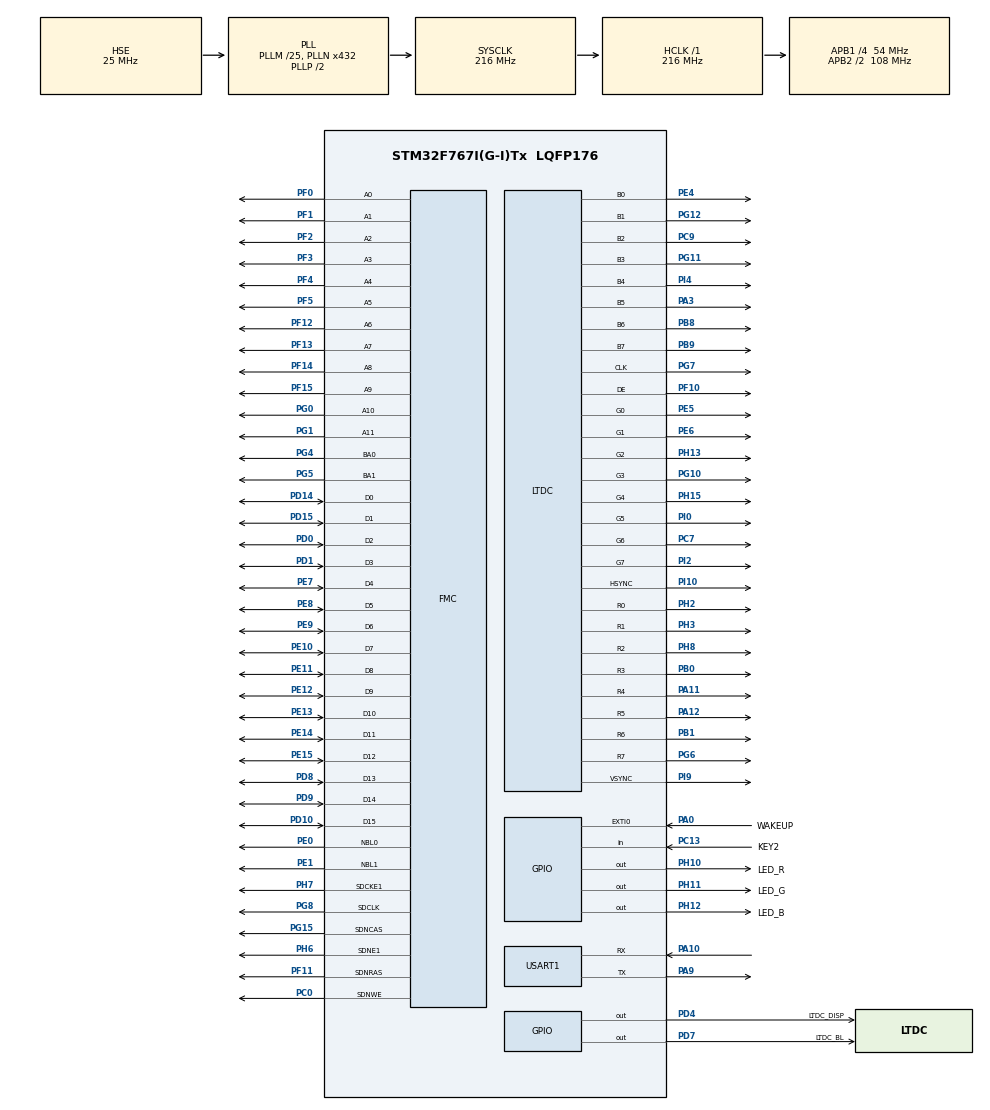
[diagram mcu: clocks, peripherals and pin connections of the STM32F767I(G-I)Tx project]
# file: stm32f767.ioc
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CORTEX_M7.CPU_DCache=Enabled
CORTEX_M7.CPU_ICache=Enabled
DMA2D.ColorMode=DMA2D_OUTPUT_ARGB8888
DMA2D.Mode=DMA2D_R2M
Dma.Request0=USART1_RX
Dma.Request1=USART1_TX
Dma.USART1_RX.0.Direction=DMA_PERIPH_TO_MEMORY
Dma.USART1_RX.0.FIFOMode=DMA_FIFOMODE_DISABLE
Dma.USART1_RX.0.Instance=DMA2_Stream2
Dma.USART1_RX.0.MemDataAlignment=DMA_MDATAALIGN_BYTE
Dma.USART1_RX.0.MemInc=DMA_MINC_ENABLE
Dma.USART1_RX.0.Mode=DMA_NORMAL
Dma.USART1_RX.0.PeriphDataAlignment=DMA_PDATAALIGN_BYTE
Dma.USART1_RX.0.PeriphInc=DMA_PINC_DISABLE
Dma.USART1_RX.0.Priority=DMA_PRIORITY_LOW
Dma.USART1_TX.1.Direction=DMA_MEMORY_TO_PERIPH
Dma.USART1_TX.1.FIFOMode=DMA_FIFOMODE_DISABLE
Dma.USART1_TX.1.Instance=DMA2_Stream7
Dma.USART1_TX.1.MemDataAlignment=DMA_MDATAALIGN_BYTE
Dma.USART1_TX.1.MemInc=DMA_MINC_ENABLE
Dma.USART1_TX.1.Mode=DMA_NORMAL
Dma.USART1_TX.1.PeriphDataAlignment=DMA_PDATAALIGN_BYTE
Dma.USART1_TX.1.PeriphInc=DMA_PINC_DISABLE
Dma.USART1_TX.1.Priority=DMA_PRIORITY_LOW
FMC.CASLatency1=FMC_SDRAM_CAS_LATENCY_3
FMC.ExitSelfRefreshDelay1=7
FMC.LoadToActiveDelay1=2
FMC.RCDDelay1=2
FMC.RPDelay1=2
FMC.RPDelay2=2
FMC.ReadBurst1=FMC_SDRAM_RBURST_ENABLE
FMC.ReadBurst2=FMC_SDRAM_RBURST_ENABLE
FMC.ReadPipeDelay1=FMC_SDRAM_RPIPE_DELAY_1
FMC.ReadPipeDelay2=FMC_SDRAM_RPIPE_DELAY_1
FMC.RowCycleDelay1=6
FMC.RowCycleDelay2=6
FMC.SDClockPeriod1=FMC_SDRAM_CLOCK_PERIOD_2
FMC.SDClockPeriod2=FMC_SDRAM_CLOCK_PERIOD_2
FMC.SelfRefreshTime1=4
FMC.WriteRecoveryTime1=2
LTDC.ActiveW=800
LTDC.Alpha_L0=255
LTDC.Alpha_L1=0
LTDC.BlendingFactor1_L0=LTDC_BLENDING_FACTOR1_PAxCA
LTDC.BlendingFactor1_L1=LTDC_BLENDING_FACTOR1_PAxCA
LTDC.BlendingFactor2_L0=LTDC_BLENDING_FACTOR2_PAxCA
LTDC.BlendingFactor2_L1=LTDC_BLENDING_FACTOR2_PAxCA
LTDC.FBStartAdress_L0=0xD0000000
LTDC.FBStartAdress_L1=0xD0200000
LTDC.HBP=46
LTDC.HFP=10
LTDC.HSync=1
LTDC.ImageHeight_L0=480
LTDC.ImageHeight_L1=480
LTDC.ImageWidth_L0=800
LTDC.ImageWidth_L1=800
LTDC.Layers=1
LTDC.PixelFormat_L0=LTDC_PIXEL_FORMAT_ARGB8888
LTDC.PixelFormat_L1=LTDC_PIXEL_FORMAT_ARGB8888
LTDC.VBP=23
LTDC.VFP=22
LTDC.WindowX1_L0=800
LTDC.WindowX1_L1=800
LTDC.WindowY1_L0=480
LTDC.WindowY1_L1=480
Mcu.Family=STM32F7
Mcu.Name=STM32F767I(G-I)Tx
Mcu.Package=LQFP176
NVIC.DMA2D_IRQn=true\:0\:0\:false\:false\:true\:true
NVIC.DMA2_Stream2_IRQn=true\:0\:0\:false\:false\:true\:false
NVIC.DMA2_Stream7_IRQn=true\:0\:0\:false\:false\:true\:false
NVIC.EXTI0_IRQn=true\:0\:0\:false\:false\:true\:true
NVIC.LTDC_IRQn=true\:0\:0\:false\:false\:true\:true
NVIC.PriorityGroup=NVIC_PRIORITYGROUP_4
PA0/WKUP.GPIO_Label=WAKEUP
PA0/WKUP.Signal=GPXTI0
PA10.Mode=Asynchronous
PA10.Signal=USART1_RX
PA11.GPIO_Speed=GPIO_SPEED_FREQ_VERY_HIGH
PA11.Mode=RGB888
PA11.Signal=LTDC_R4
PA12.GPIO_Speed=GPIO_SPEED_FREQ_VERY_HIGH
PA12.Mode=RGB888
PA12.Signal=LTDC_R5
PA3.GPIO_Speed=GPIO_SPEED_FREQ_VERY_HIGH
PA3.Mode=RGB888
PA3.Signal=LTDC_B5
PA9.Mode=Asynchronous
PA9.Signal=USART1_TX
PB0.GPIO_Speed=GPIO_SPEED_FREQ_VERY_HIGH
PB0.Mode=RGB888
PB0.Signal=LTDC_R3
PB1.GPIO_Speed=GPIO_SPEED_FREQ_VERY_HIGH
PB1.Mode=RGB888
PB1.Signal=LTDC_R6
PB8.GPIO_Speed=GPIO_SPEED_FREQ_VERY_HIGH
PB8.Mode=RGB888
PB8.Signal=LTDC_B6
PB9.GPIO_Speed=GPIO_SPEED_FREQ_VERY_HIGH
PB9.Mode=RGB888
PB9.Signal=LTDC_B7
PC0.Signal=FMC_SDNWE
PC13.GPIO_Label=KEY2
PC13.Signal=GPIO_Input
PC7.GPIO_Speed=GPIO_SPEED_FREQ_VERY_HIGH
PC7.Mode=RGB888
PC7.Signal=LTDC_G6
PC9.Mode=RGB888
PC9.Signal=LTDC_B2
PD0.Signal=FMC_D2_DA2
PD1.Signal=FMC_D3_DA3
PD10.Signal=FMC_D15_DA15
PD14.Signal=FMC_D0_DA0
PD15.Signal=FMC_D1_DA1
PD4.GPIO_Label=LTDC_DISP
PD4.GPIO_PuPd=GPIO_PULLUP
PD4.GPIO_Speed=GPIO_SPEED_FREQ_HIGH
PD4.Signal=GPIO_Output
PD7.GPIO_Label=LTDC_BL
PD7.GPIO_PuPd=GPIO_PULLUP
PD7.GPIO_Speed=GPIO_SPEED_FREQ_HIGH
PD7.Signal=GPIO_Output
PD8.Signal=FMC_D13_DA13
PD9.Signal=FMC_D14_DA14
PE0.Signal=FMC_NBL0
PE1.Signal=FMC_NBL1
PE10.Signal=FMC_D7_DA7
PE11.Signal=FMC_D8_DA8
PE12.Signal=FMC_D9_DA9
PE13.Signal=FMC_D10_DA10
PE14.Signal=FMC_D11_DA11
PE15.Signal=FMC_D12_DA12
PE4.Mode=RGB888
PE4.Signal=LTDC_B0
PE5.Mode=RGB888
PE5.Signal=LTDC_G0
PE6.Mode=RGB888
PE6.Signal=LTDC_G1
PE7.Signal=FMC_D4_DA4
PE8.Signal=FMC_D5_DA5
PE9.Signal=FMC_D6_DA6
PF0.Signal=FMC_A0
PF1.Signal=FMC_A1
PF10.GPIO_Speed=GPIO_SPEED_FREQ_VERY_HIGH
PF10.Mode=RGB888
PF10.Signal=LTDC_DE
PF11.Signal=FMC_SDNRAS
PF12.Signal=FMC_A6
PF13.Signal=FMC_A7
PF14.Signal=FMC_A8
PF15.Signal=FMC_A9
PF2.Signal=FMC_A2
PF3.Signal=FMC_A3
PF4.Signal=FMC_A4
PF5.Signal=FMC_A5
PG0.Signal=FMC_A10
PG1.Signal=FMC_A11
PG10.GPIO_Speed=GPIO_SPEED_FREQ_VERY_HIGH
PG10.Mode=RGB888
PG10.Signal=LTDC_G3
PG11.GPIO_Speed=GPIO_SPEED_FREQ_VERY_HIGH
PG11.Mode=RGB888
PG11.Signal=LTDC_B3
PG12.Mode=RGB888
PG12.Signal=LTDC_B1
PG15.Signal=FMC_SDNCAS
PG4.Signal=FMC_A14_BA0
PG5.Signal=FMC_A15_BA1
PG6.GPIO_Speed=GPIO_SPEED_FREQ_VERY_HIGH
PG6.Mode=RGB888
PG6.Signal=LTDC_R7
PG7.GPIO_Speed=GPIO_SPEED_FREQ_VERY_HIGH
PG7.Mode=RGB888
PG7.Signal=LTDC_CLK
PG8.Signal=FMC_SDCLK
PH0/OSC_IN.Mode=HSE-External-Oscillator
PH0/OSC_IN.Signal=RCC_OSC_IN
PH1/OSC_OUT.Mode=HSE-External-Oscillator
PH1/OSC_OUT.Signal=RCC_OSC_OUT
PH10.GPIO_Label=LED_R
PH10.GPIO_PuPd=GPIO_PULLUP
PH10.Signal=GPIO_Output
PH11.GPIO_Label=LED_G
PH11.GPIO_PuPd=GPIO_PULLUP
PH11.Signal=GPIO_Output
PH12.GPIO_Label=LED_B
PH12.GPIO_PuPd=GPIO_PULLUP
PH12.Signal=GPIO_Output
PH13.GPIO_Speed=GPIO_SPEED_FREQ_VERY_HIGH
PH13.Mode=RGB888
PH13.Signal=LTDC_G2
PH15.GPIO_Speed=GPIO_SPEED_FREQ_VERY_HIGH
PH15.Mode=RGB888
PH15.Signal=LTDC_G4
PH2.Mode=RGB888
PH2.Signal=LTDC_R0
PH3.GPIO_Speed=GPIO_SPEED_FREQ_VERY_HIGH
PH3.Mode=RGB888
PH3.Signal=LTDC_R1
PH6.Mode=SdramChipSelect2_1
PH6.Signal=FMC_SDNE1
PH7.Mode=SdramChipSelect2_1
PH7.Signal=FMC_SDCKE1
PH8.GPIO_Speed=GPIO_SPEED_FREQ_VERY_HIGH
PH8.Mode=RGB888
PH8.Signal=LTDC_R2
PI0.GPIO_Speed=GPIO_SPEED_FREQ_VERY_HIGH
PI0.Mode=RGB888
PI0.Signal=LTDC_G5
PI10.Mode=RGB888
PI10.Signal=LTDC_HSYNC
PI2.GPIO_Speed=GPIO_SPEED_FREQ_VERY_HIGH
PI2.Mode=RGB888
PI2.Signal=LTDC_G7
PI4.GPIO_Speed=GPIO_SPEED_FREQ_VERY_HIGH
PI4.Mode=RGB888
PI4.Signal=LTDC_B4
PI9.GPIO_Speed=GPIO_SPEED_FREQ_VERY_HIGH
PI9.Mode=RGB888
PI9.Signal=LTDC_VSYNC
ProjectManager.HeapSize=0x200
ProjectManager.StackSize=0x1000
ProjectManager.TargetToolchain=MDK-ARM V5
RCC.AHBFreq_Value=216000000
RCC.APB1CLKDivider=RCC_HCLK_DIV4
RCC.APB1Freq_Value=54000000
RCC.APB1TimFreq_Value=108000000
RCC.APB2CLKDivider=RCC_HCLK_DIV2
RCC.APB2Freq_Value=108000000
RCC.APB2TimFreq_Value=216000000
RCC.CortexFreq_Value=216000000
RCC.HCLKFreq_Value=216000000
RCC.HSE_VALUE=25000000
RCC.HSI_VALUE=16000000
RCC.LSE_VALUE=32768
RCC.PLLM=25
RCC.PLLN=432
RCC.PLLQ=9
RCC.PLLSAIR=5
RCC.PLLSAIRDiv=RCC_PLLSAIDIVR_4
RCC.PLLSourceVirtual=RCC_PLLSOURCE_HSE
RCC.SYSCLKFreq_VALUE=216000000
RCC.SYSCLKSource=RCC_SYSCLKSOURCE_PLLCLK
RCC.USBFreq_Value=48000000
RCC.VCOOutputFreq_Value=432000000
SH.FMC_A0.0=FMC_A0,12b-sda1
SH.FMC_A1.0=FMC_A1,12b-sda1
SH.FMC_A10.0=FMC_A10,12b-sda1
SH.FMC_A11.0=FMC_A11,12b-sda1
SH.FMC_A14_BA0.0=FMC_BA0,FourSdramBanks1
SH.FMC_A15_BA1.0=FMC_BA1,FourSdramBanks1
SH.FMC_A2.0=FMC_A2,12b-sda1
SH.FMC_A3.0=FMC_A3,12b-sda1
SH.FMC_A4.0=FMC_A4,12b-sda1
SH.FMC_A5.0=FMC_A5,12b-sda1
SH.FMC_A6.0=FMC_A6,12b-sda1
SH.FMC_A7.0=FMC_A7,12b-sda1
SH.FMC_A8.0=FMC_A8,12b-sda1
SH.FMC_A9.0=FMC_A9,12b-sda1
SH.FMC_D0_DA0.0=FMC_D0,sd-16b-d1
SH.FMC_D10_DA10.0=FMC_D10,sd-16b-d1
SH.FMC_D11_DA11.0=FMC_D11,sd-16b-d1
SH.FMC_D12_DA12.0=FMC_D12,sd-16b-d1
SH.FMC_D13_DA13.0=FMC_D13,sd-16b-d1
SH.FMC_D14_DA14.0=FMC_D14,sd-16b-d1
SH.FMC_D15_DA15.0=FMC_D15,sd-16b-d1
SH.FMC_D1_DA1.0=FMC_D1,sd-16b-d1
SH.FMC_D2_DA2.0=FMC_D2,sd-16b-d1
SH.FMC_D3_DA3.0=FMC_D3,sd-16b-d1
SH.FMC_D4_DA4.0=FMC_D4,sd-16b-d1
SH.FMC_D5_DA5.0=FMC_D5,sd-16b-d1
SH.FMC_D6_DA6.0=FMC_D6,sd-16b-d1
SH.FMC_D7_DA7.0=FMC_D7,sd-16b-d1
SH.FMC_D8_DA8.0=FMC_D8,sd-16b-d1
SH.FMC_D9_DA9.0=FMC_D9,sd-16b-d1
SH.FMC_NBL0.0=FMC_NBL0,Sd2ByteEnable1
SH.FMC_NBL1.0=FMC_NBL1,Sd2ByteEnable1
SH.FMC_SDCLK.0=FMC_SDCLK,12b-sda1
SH.FMC_SDNCAS.0=FMC_SDNCAS,12b-sda1
SH.FMC_SDNRAS.0=FMC_SDNRAS,12b-sda1
SH.FMC_SDNWE.0=FMC_SDNWE,12b-sda1
USART1.VirtualMode-Asynchronous=VM_ASYNC
VP_DMA2D_VS_DMA2D.Mode=DMA2D_Activate
board=custom

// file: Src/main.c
/**
  ******************************************************************************
  * @file           : main.c
  * @brief          : Main program body
  ******************************************************************************
  ** This notice applies to any and all portions of this file
  * that are not between comment pairs USER CODE BEGIN and
  * USER CODE END. Other portions of this file, whether
  * inserted by the user or by software development tools
  * are owned by their respective copyright owners.
  *
  * COPYRIGHT(c) 2018 STMicroelectronics
  *
  * Redistribution and use in source and binary forms, with or without modification,
  * are permitted provided that the following conditions are met:
  *   1. Redistributions of source code must retain the above copyright notice,
  *      this list of conditions and the following disclaimer.
  *   2. Redistributions in binary form must reproduce the above copyright notice,
  *      this list of conditions and the following disclaimer in the documentation
  *      and/or other materials provided with the distribution.
  *   3. Neither the name of STMicroelectronics nor the names of its contributors
  *      may be used to endorse or promote products derived from this software
  *      without specific prior written permission.
  *
  * THIS SOFTWARE IS PROVIDED BY THE COPYRIGHT HOLDERS AND CONTRIBUTORS "AS IS"
  * AND ANY EXPRESS OR IMPLIED WARRANTIES, INCLUDING, BUT NOT LIMITED TO, THE
  * IMPLIED WARRANTIES OF MERCHANTABILITY AND FITNESS FOR A PARTICULAR PURPOSE ARE
  * DISCLAIMED. IN NO EVENT SHALL THE COPYRIGHT HOLDER OR CONTRIBUTORS BE LIABLE
  * FOR ANY DIRECT, INDIRECT, INCIDENTAL, SPECIAL, EXEMPLARY, OR CONSEQUENTIAL
  * DAMAGES (INCLUDING, BUT NOT LIMITED TO, PROCUREMENT OF SUBSTITUTE GOODS OR
  * SERVICES; LOSS OF USE, DATA, OR PROFITS; OR BUSINESS INTERRUPTION) HOWEVER
  * CAUSED AND ON ANY THEORY OF LIABILITY, WHETHER IN CONTRACT, STRICT LIABILITY,
  * OR TORT (INCLUDING NEGLIGENCE OR OTHERWISE) ARISING IN ANY WAY OUT OF THE USE
  * OF THIS SOFTWARE, EVEN IF ADVISED OF THE POSSIBILITY OF SUCH DAMAGE.
  *
  ******************************************************************************
  */
#include "main.h"
#include "stm32f7xx_hal.h"
#include "dma.h"
#include "dma2d.h"
#include "ltdc.h"
#include "usart.h"
#include "gpio.h"
#include "fmc.h"

/* USER CODE BEGIN Includes */
#include "stdio.h"
#include <string.h>
#include "../Drivers/BSP/Components/std800480/std800480.h"
//#include "image1.h"

/* USER CODE END Includes */

/* USER CODE BEGIN PV */
/* Private variables ---------------------------------------------------------*/
uint32_t read_buffer[200];

/* USER CODE END PV */

void SystemClock_Config(void);

/* USER CODE BEGIN PFP */
/* Private function prototypes -----------------------------------------------*/
void lcd_init(void);
void sdram_init(void);
/* USER CODE END PFP */

int main(void)
{

  /* Enable I-Cache-------------------------------------------------------------*/
  SCB_EnableICache();

  /* Enable D-Cache-------------------------------------------------------------*/
  SCB_EnableDCache();

  /* MCU Configuration----------------------------------------------------------*/

  /* Reset of all peripherals, Initializes the Flash interface and the Systick. */
  HAL_Init();

  /* Configure the system clock */
  SystemClock_Config();

  /* Initialize all configured peripherals */
  MX_GPIO_Init();
  MX_DMA_Init();
  MX_USART1_UART_Init();
  MX_FMC_Init();
  MX_LTDC_Init();
  MX_DMA2D_Init();
  /* USER CODE BEGIN 2 */
  BSP_LED_Off(LED_R);
  BSP_LED_Off(LED_B);
  BSP_LED_Off(LED_G);

  LED_BLUE;

  sdram_init();
  lcd_drv = &std800480_drv;
//  lcd_init();
  lcd_drv->Init();
  lcd_drv->LayerInit(0,(uint32_t)0xD0000000,ARGB8888);
  lcd_drv->LayerInit(1,(uint32_t)0xD0200000,ARGB8888);
  lcd_drv->DisplayOn();
  lcd_drv->SelectLayer(0);
  lcd_drv->Clear(LCD_COLOR_BLACK);
  lcd_drv->SelectLayer(1);
  lcd_drv->Clear(LCD_COLOR_BLACK);

  lcd_drv->SetTransparency(0,255);
  lcd_drv->SetTransparency(1,0);

  LED_GREEN;

  printf("%s\n","-----D000 after clear-----");
  uint32_t i;
  uint8_t ubReaddata_8b=0;
  for (i=0; i<200; i++) {
    ubReaddata_8b = *(__IO uint8_t*)(0xD0000000 + i);
    printf("%x ",ubReaddata_8b);
  }

  printf("\n%s\n","-----D000 after clear-----");

  printf("%s\n","-----D020 after clear-----");

  for (i=0; i<200; i++) {
    ubReaddata_8b = *(__IO uint8_t*)(0xD0200000 + i);
    printf("%x ",ubReaddata_8b);
  }

  printf("\n%s\n","-----D020 after clear-----");
  /* USER CODE END 2 */

  /* Infinite loop */
  while (1)
  {

  /* USER CODE BEGIN 3 */
    lcd_drv->Test();
  }
  /* USER CODE END 3 */

}

void SystemClock_Config(void)
{

  RCC_OscInitTypeDef RCC_OscInitStruct;
  RCC_ClkInitTypeDef RCC_ClkInitStruct;
  RCC_PeriphCLKInitTypeDef PeriphClkInitStruct;

    /**Configure the main internal regulator output voltage
    */
  __HAL_RCC_PWR_CLK_ENABLE();

  __HAL_PWR_VOLTAGESCALING_CONFIG(PWR_REGULATOR_VOLTAGE_SCALE1);

    /**Initializes the CPU, AHB and APB busses clocks
    */
  RCC_OscInitStruct.OscillatorType = RCC_OSCILLATORTYPE_HSE;
  RCC_OscInitStruct.HSEState = RCC_HSE_ON;
  RCC_OscInitStruct.PLL.PLLState = RCC_PLL_ON;
  RCC_OscInitStruct.PLL.PLLSource = RCC_PLLSOURCE_HSE;
  RCC_OscInitStruct.PLL.PLLM = 25;
  RCC_OscInitStruct.PLL.PLLN = 432;
  RCC_OscInitStruct.PLL.PLLP = RCC_PLLP_DIV2;
  RCC_OscInitStruct.PLL.PLLQ = 9;
  if (HAL_RCC_OscConfig(&RCC_OscInitStruct) != HAL_OK)
  {
    _Error_Handler(__FILE__, __LINE__);
  }

    /**Activate the Over-Drive mode
    */
  if (HAL_PWREx_EnableOverDrive() != HAL_OK)
  {
    _Error_Handler(__FILE__, __LINE__);
  }

    /**Initializes the CPU, AHB and APB busses clocks
    */
  RCC_ClkInitStruct.ClockType = RCC_CLOCKTYPE_HCLK|RCC_CLOCKTYPE_SYSCLK
                              |RCC_CLOCKTYPE_PCLK1|RCC_CLOCKTYPE_PCLK2;
  RCC_ClkInitStruct.SYSCLKSource = RCC_SYSCLKSOURCE_PLLCLK;
  RCC_ClkInitStruct.AHBCLKDivider = RCC_SYSCLK_DIV1;
  RCC_ClkInitStruct.APB1CLKDivider = RCC_HCLK_DIV4;
  RCC_ClkInitStruct.APB2CLKDivider = RCC_HCLK_DIV2;

  if (HAL_RCC_ClockConfig(&RCC_ClkInitStruct, FLASH_LATENCY_7) != HAL_OK)
  {
    _Error_Handler(__FILE__, __LINE__);
  }

  PeriphClkInitStruct.PeriphClockSelection = RCC_PERIPHCLK_LTDC|RCC_PERIPHCLK_USART1;
  PeriphClkInitStruct.PLLSAI.PLLSAIN = 192;
  PeriphClkInitStruct.PLLSAI.PLLSAIR = 5;
  PeriphClkInitStruct.PLLSAI.PLLSAIQ = 2;
  PeriphClkInitStruct.PLLSAI.PLLSAIP = RCC_PLLSAIP_DIV2;
  PeriphClkInitStruct.PLLSAIDivQ = 1;
  PeriphClkInitStruct.PLLSAIDivR = RCC_PLLSAIDIVR_4;
  PeriphClkInitStruct.Usart1ClockSelection = RCC_USART1CLKSOURCE_PCLK2;
  if (HAL_RCCEx_PeriphCLKConfig(&PeriphClkInitStruct) != HAL_OK)
  {
    _Error_Handler(__FILE__, __LINE__);
  }

    /**Configure the Systick interrupt time
    */
  HAL_SYSTICK_Config(HAL_RCC_GetHCLKFreq()/1000);

    /**Configure the Systick
    */
  HAL_SYSTICK_CLKSourceConfig(SYSTICK_CLKSOURCE_HCLK);

  /* SysTick_IRQn interrupt configuration */
  HAL_NVIC_SetPriority(SysTick_IRQn, 0, 0);
}

/* USER CODE BEGIN 4 */
/**
  * @brief EXTI line detection callbacks
  * @param GPIO_Pin: Specifies the pins connected EXTI line
  * @retval None
  */
void HAL_GPIO_EXTI_Callback(uint16_t GPIO_Pin)
{
  if(GPIO_Pin == GPIO_PIN_0)
  {
    /* Toggle LED1 */
    BSP_LED_Toggle(LED_B);
  }
}

void HAL_UART_RxCpltCallback(UART_HandleTypeDef *huart)
{

//    if(huart->Instance == USART1)   // 判断是由哪个串口触发的中断
//    {
//      HAL_UART_Transmit(&huart1,Rx_Buffer,1,100);    // 接收到数据马上使用串口1发送出去
//      HAL_UART_Receive_IT(&huart1,Rx_Buffer,1);      // 重新使能串口1接收中断
//    }
}

void sdram_init(void)
{
  sdram_drv = &is42s16400j_drv;
  sdram_drv->Init(&hsdram1);
  printf("SDRAM Sequence init OK\n");
//  sdram_drv->Test();
//  sdram_drv->ReadBuffer(read_buffer,LCD_FB_START_ADDRESS,200);
//  int i;
//  for (i=0; i<200; i++) printf("%c ",read_buffer[i]);
//  printf("\n");
//  sdram_drv->ReadBuffer(read_buffer,0xD0200000,200);
//  for (i=0; i<200; i++) printf("%c ",read_buffer[i]);

  printf("%s\n","-----D000 before clear-----");
  uint32_t i;
  uint8_t ubReaddata_8b=0;
  for (i=0; i<200; i++) {
    ubReaddata_8b = *(__IO uint8_t*)(0xD0000000 + i);
    printf("%x ",ubReaddata_8b);
  }

  printf("\n%s\n","-----D000 before clear-----");

    printf("%s\n","-----D020 before clear-----");
  for (i=0; i<200; i++) {
    ubReaddata_8b = *(__IO uint8_t*)(0xD0000000 + i);
    printf("%x ",ubReaddata_8b);
  }

  printf("\n%s\n","-----D020 before clear-----");
}

void lcd_init(void)
{
//  lcd_drv = &std800480_drv;
  lcd_drv->Init();
  sdram_init();
}

/* USER CODE END 4 */

void _Error_Handler(char *file, int line)
{
  while(1)
  {
  }
}

/************************ (C) COPYRIGHT STMicroelectronics *****END OF FILE****/
